# neorv32 register map
Vendor: github.com/stnolting/neorv32; Series: RISC-V; File version: 1.13.7
CPU: other r1p0, little endian, MPU, FPU, I-cache, D-cache, ITCM, DTCM, 4 interrupt priority bits
Address unit: 16 bits
Registers are 32-bit, read-write, reset 0x0 unless marked. A register's access mark holds for its fields unless they carry their own. Offsets are from the block's base; [hi:lo] are bit positions.

## SPI — Serial peripheral interface controller
Base 0xFFF80000
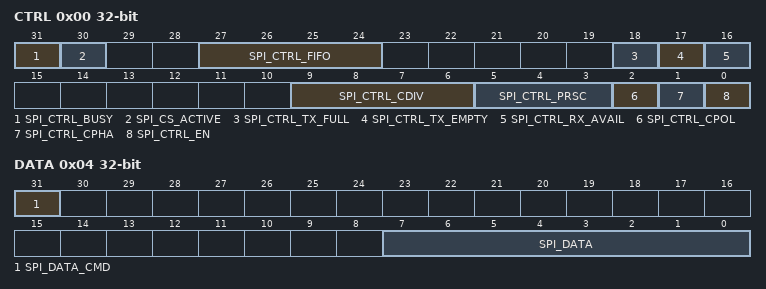
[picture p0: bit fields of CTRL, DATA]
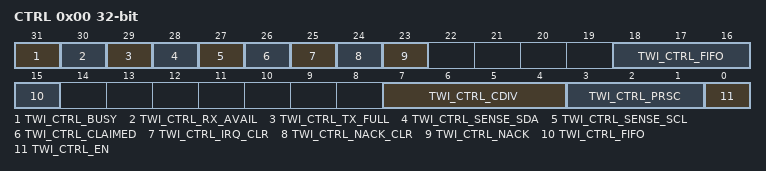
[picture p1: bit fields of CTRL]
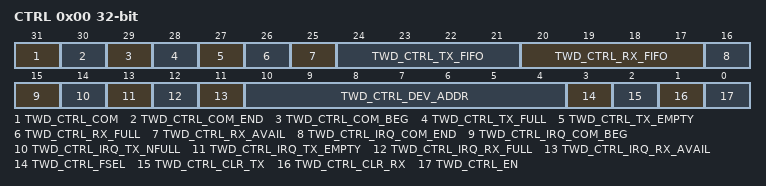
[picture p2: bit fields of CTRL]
0x00 CTRL — Control register
  [31] SPI_CTRL_BUSY ro — SPI busy flag (transmission in progress and TX FIFO not empty)
  [30] SPI_CS_ACTIVE ro — Set if a chip-select line is active
  [27:24] SPI_CTRL_FIFO ro — log2(FIFO size)
  [18] SPI_CTRL_TX_FULL ro — TX FIFO is full
  [17] SPI_CTRL_TX_EMPTY ro — TX FIFO is empty
  [16] SPI_CTRL_RX_AVAIL ro — RX FIFO data available (RX FIFO not empty)
  [9:6] SPI_CTRL_CDIV — SPI clock divider
  [5:3] SPI_CTRL_PRSC — Clock prescaler select
  [2] SPI_CTRL_CPOL — Clock polarity
  [1] SPI_CTRL_CPHA — Clock phase
  [0] SPI_CTRL_EN — SPI enable flag
0x04 DATA read-modifies
  [31] SPI_DATA_CMD wo — SPI TX data (0) / command (1) select
  [7:0] SPI_DATA — RX data / TX data/command (via FIFOs)

## TWI — Two-wire interface controller
Base 0xFFF90000
0x00 CTRL — Control register
  [31] TWI_CTRL_BUSY ro — Bus engine busy or TX FIFO not empty
  [30] TWI_CTRL_RX_AVAIL ro — RX FIFO not empty (data available)
  [29] TWI_CTRL_TX_FULL ro — TX FIFO full
  [28] TWI_CTRL_SENSE_SDA ro — Current state of the SDA bus line
  [27] TWI_CTRL_SENSE_SCL ro — Current state of the SCL bus line
  [26] TWI_CTRL_CLAIMED ro — Bus is claimed by controller
  [25] TWI_CTRL_IRQ_CLR wo — Clear interrupt request
  [24] TWI_CTRL_NACK_CLR wo — Clear NACK flag TWI_CTRL_NACK
  [23] TWI_CTRL_NACK ro — Set if any TX transmission returned a NACK, sticky until cleared
  [18:15] TWI_CTRL_FIFO ro — log2(TWI FIFO size)
  [7:4] TWI_CTRL_CDIV — Clock divider
  [3:1] TWI_CTRL_PRSC — Clock prescaler select
  [0] TWI_CTRL_EN — TWI enable
0x04 DCMD read-modifies — RX/TX data and command register

## TWD — Two-wire device controller
Base 0xFFEA0000
0x00 CTRL — Control register
  [31] TWD_CTRL_COM ro — active communication
  [30] TWD_CTRL_COM_END — communication has ended; clear by writing 1
  [29] TWD_CTRL_COM_BEG — communication has started; clear by writing 1
  [28] TWD_CTRL_TX_FULL ro — TX FIFO full
  [27] TWD_CTRL_TX_EMPTY ro — TX FIFO empty
  [26] TWD_CTRL_RX_FULL ro — RX FIFO full
  [25] TWD_CTRL_RX_AVAIL ro — RX FIFO data available
  [24:21] TWD_CTRL_TX_FIFO ro — log2(TWD TX FIFO size)
  [20:17] TWD_CTRL_RX_FIFO ro — log2(TWD RX FIFO size)
  [16] TWD_CTRL_IRQ_COM_END — IRQ if end of communication
  [15] TWD_CTRL_IRQ_COM_BEG — IRQ if begin of communication
  [14] TWD_CTRL_IRQ_TX_NFULL — IRQ if TX FIFO is not full
  [13] TWD_CTRL_IRQ_TX_EMPTY — IRQ if TX FIFO empty
  [12] TWD_CTRL_IRQ_RX_FULL — IRQ if RX FIFO full
  [11] TWD_CTRL_IRQ_RX_AVAIL — IRQ if RX FIFO data available
  [10:4] TWD_CTRL_DEV_ADDR — Device address (7-bit)
  [3] TWD_CTRL_FSEL — Bus sample clock / filter select
  [2] TWD_CTRL_CLR_TX wo — Clear TX FIFO, flag auto-clears
  [1] TWD_CTRL_CLR_RX wo — Clear RX FIFO, flag auto-clears
  [0] TWD_CTRL_EN — TWD enable flag
0x04 DATA read-modifies — RX/TX data register
  [7:0] TWI_DATA — RX/TX data FIFO access

## TRNG — True random number generator
Base 0xFFFA0000
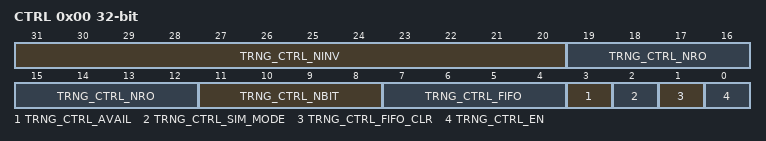
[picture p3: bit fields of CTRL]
0x00 CTRL — Control and data register
  [31:20] TRNG_CTRL_NINV ro — Number of inverters in first ring-oscillator
  [19:12] TRNG_CTRL_NRO ro — Total number of ring-oscillators
  [11:8] TRNG_CTRL_NBIT ro — log2(number of raw bits) processed for one output byte
  [7:4] TRNG_CTRL_FIFO ro — log2(TRNG FIFO depth)
  [3] TRNG_CTRL_AVAIL ro — Random data available
  [2] TRNG_CTRL_SIM_MODE ro — TRNG simulation mode (PRNG!) active
  [1] TRNG_CTRL_FIFO_CLR wo — Clear data FIFO when set (flag auto clears)
  [0] TRNG_CTRL_EN — TRNG enable flag
0x04 DATA ro read-modifies — Random data
  [7:0] TRNG_DATA
